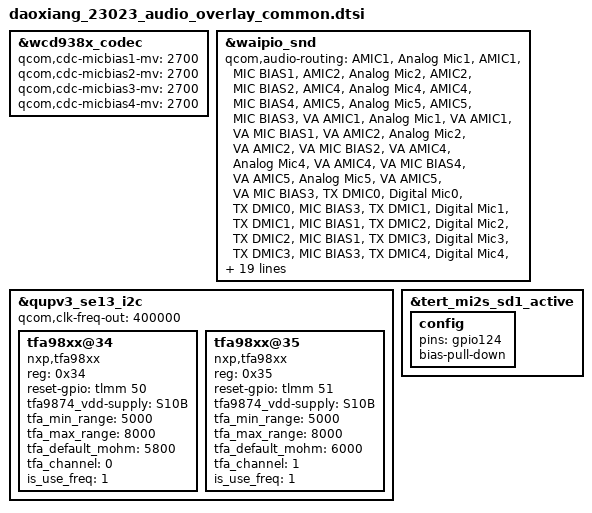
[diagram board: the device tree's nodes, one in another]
/* #ifdef OPLUS_ARCH_EXTENDS */
&wcd938x_codec {
	qcom,cdc-micbias1-mv = <2700>;
	qcom,cdc-micbias2-mv = <2700>;
	qcom,cdc-micbias3-mv = <2700>;
	qcom,cdc-micbias4-mv = <2700>;
};

&waipio_snd {
	qcom,audio-routing =
		"AMIC1", "Analog Mic1",
		"AMIC1", "MIC BIAS1",
		"AMIC2", "Analog Mic2",
		"AMIC2", "MIC BIAS2",
		"AMIC4", "Analog Mic4",
		"AMIC4", "MIC BIAS4",
		"AMIC5", "Analog Mic5",
		"AMIC5", "MIC BIAS3",
		"VA AMIC1", "Analog Mic1",
		"VA AMIC1", "VA MIC BIAS1",
		"VA AMIC2", "Analog Mic2",
		"VA AMIC2", "VA MIC BIAS2",
		"VA AMIC4", "Analog Mic4",
		"VA AMIC4", "VA MIC BIAS4",
		"VA AMIC5", "Analog Mic5",
		"VA AMIC5", "VA MIC BIAS3",
		"TX DMIC0", "Digital Mic0",
		"TX DMIC0", "MIC BIAS3",
		"TX DMIC1", "Digital Mic1",
		"TX DMIC1", "MIC BIAS1",
		"TX DMIC2", "Digital Mic2",
		"TX DMIC2", "MIC BIAS1",
		"TX DMIC3", "Digital Mic3",
		"TX DMIC3", "MIC BIAS3",
		"TX DMIC4", "Digital Mic4",
		"TX DMIC4", "MIC BIAS4",
		"IN1_HPHL", "HPHL_OUT",
		"IN2_HPHR", "HPHR_OUT",
		"IN3_AUX", "AUX_OUT",
		"HAP_IN", "PCM_OUT",
		"RX_TX DEC0_INP", "TX DEC0 MUX",
		"RX_TX DEC1_INP", "TX DEC1 MUX",
		"RX_TX DEC2_INP", "TX DEC2 MUX",
		"RX_TX DEC3_INP", "TX DEC3 MUX",
		"TX SWR_INPUT", "WCD_TX_OUTPUT",
		"VA SWR_INPUT", "VA_SWR_CLK",
		"VA SWR_INPUT", "WCD_TX_OUTPUT",
		"VA_AIF1 CAP", "VA_SWR_CLK",
		"VA_AIF2 CAP", "VA_SWR_CLK",
		"VA_AIF3 CAP", "VA_SWR_CLK",
		"VA DMIC0", "Digital Mic0",
		"VA DMIC1", "Digital Mic1",
		"VA DMIC2", "Digital Mic2",
		"VA DMIC3", "Digital Mic3",
		"VA DMIC4", "Digital Mic4",
		"VA DMIC0", "VA MIC BIAS3",
		"VA DMIC1", "VA MIC BIAS1",
		"VA DMIC2", "VA MIC BIAS1",
		"VA DMIC3", "VA MIC BIAS3",
		"VA DMIC4", "VA MIC BIAS4";

	qcom,msm-mbhc-hs-mic-max-threshold-mv = <2600>;
	qcom,msm-mbhc-hs-mic-min-threshold-mv = <112>; /* 75*2700/1800 */
	oplus,mbhc-check-cross-conn = <1>;
};

&qupv3_se13_i2c {
	status = "ok";
	qcom,clk-freq-out = <400000>;
	tfa98xx@34 {
		compatible = "nxp,tfa98xx";
		reg = <0x34>;
		reset-gpio = <&tlmm 50 0x00>;
		tfa9874_vdd-supply = <&S10B>;
		tfa_min_range = <5000>;
		tfa_max_range = <8000>;
		tfa_default_mohm = <5800>;
		tfa_channel = <0>;
		status = "ok";
		is_use_freq = <1>;
	};
	tfa98xx@35 {
		compatible = "nxp,tfa98xx";
		reg = <0x35>;
		reset-gpio = <&tlmm 51 0x00>;
		tfa9874_vdd-supply = <&S10B>;
		tfa_min_range = <5000>;
		tfa_max_range = <8000>;
		tfa_default_mohm = <6000>;
		tfa_channel = <1>;
		status = "ok";
		is_use_freq = <1>;
	};
};

&tert_mi2s_sd1_active {
	config {
		pins = "gpio124";
		bias-pull-down;
	};
};

/* OPLUS_ARCH_EXTENDS */
